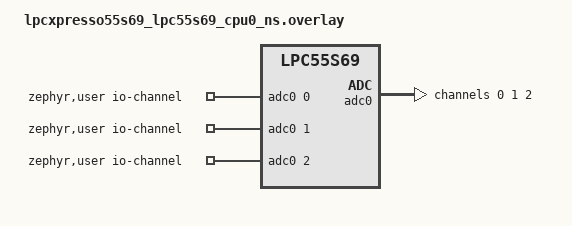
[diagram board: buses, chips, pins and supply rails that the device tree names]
/*
 * Copyright (c) 2022 Kumar Gala <galak@kernel.org>
 *
 * SPDX-License-Identifier: Apache-2.0
 */

tst_dma0: &dma0 {};

#include <zephyr/dt-bindings/adc/mcux-lpadc.h>

/ {
	zephyr,user {
		io-channels = <&adc0 0>, <&adc0 1>, <&adc0 2>;
	};
};

&adc0 {
	#address-cells = <1>;
	#size-cells = <0>;
	channel@0 {
		reg = <0>;
		zephyr,gain = "ADC_GAIN_1";
		zephyr,reference = "ADC_REF_EXTERNAL0";
		zephyr,vref-mv = <3300>;
		zephyr,acquisition-time = <ADC_ACQ_TIME_DEFAULT>;
		zephyr,resolution = <13>;
		zephyr,input-positive = <MCUX_LPADC_CH0A>;
	};
	channel@1 {
		reg = <1>;
		zephyr,gain = "ADC_GAIN_1";
		zephyr,reference = "ADC_REF_EXTERNAL0";
		zephyr,vref-mv = <3300>;
		zephyr,acquisition-time = <ADC_ACQ_TIME_DEFAULT>;
		zephyr,resolution = <16>;
		zephyr,input-positive = <MCUX_LPADC_CH4A>;
	};
	channel@2 {
		reg = <2>;
		zephyr,gain = "ADC_GAIN_1";
		zephyr,reference = "ADC_REF_EXTERNAL0";
		zephyr,vref-mv = <3300>;
		zephyr,acquisition-time = <ADC_ACQ_TIME_DEFAULT>;
		zephyr,resolution = <12>;
		zephyr,input-positive = <MCUX_LPADC_CH4B>;
	};
};
